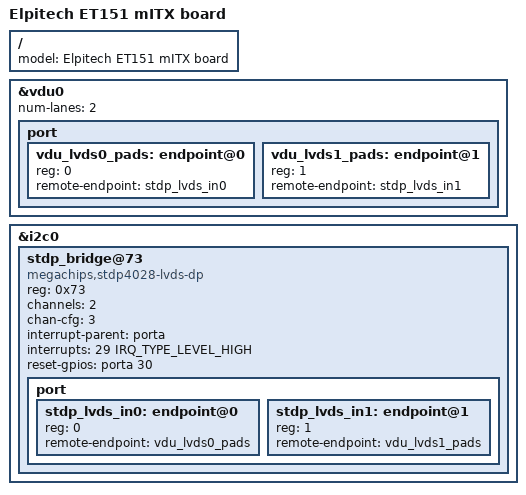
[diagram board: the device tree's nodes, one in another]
// SPDX-License-Identifier: GPL-2.0
/*
 * Elpitech ET151 Mini-ITX board device tree
 */

/dts-v1/;

#include "bm-et151.dtsi"

/ {
	model = "Elpitech ET151 mITX board";
};

&vdu0 {
	status = "okay";
	num-lanes = <2>;
	port {
		#address-cells = <1>;
		#size-cells = <0>;
		vdu_lvds0_pads: endpoint@0 {
			reg = <0>;
			remote-endpoint = <&stdp_lvds_in0>;
		};
		vdu_lvds1_pads: endpoint@1 {
			reg = <1>;
			remote-endpoint = <&stdp_lvds_in1>;
		};
	};
};

&i2c0 {
	stdp_bridge@73 {
		compatible = "megachips,stdp4028-lvds-dp";
		reg = <0x73>;
		channels = <2>;
		chan-cfg = <3>;
		interrupt-parent = <&porta>;
		interrupts = <29 IRQ_TYPE_LEVEL_HIGH>;
		reset-gpios = <&porta 30 GPIO_ACTIVE_HIGH>;

		port {
			#address-cells = <1>;
			#size-cells = <0>;

			stdp_lvds_in0: endpoint@0 {
				reg = <0>;
				remote-endpoint = <&vdu_lvds0_pads>;
			};
			stdp_lvds_in1: endpoint@1 {
				reg = <1>;
				remote-endpoint = <&vdu_lvds1_pads>;
			};
		};
	};
};
